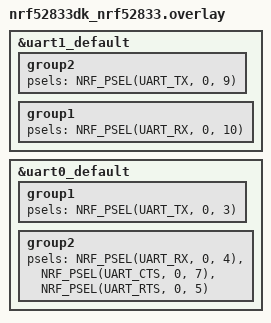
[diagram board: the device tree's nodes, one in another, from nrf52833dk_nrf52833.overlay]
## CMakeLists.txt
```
#*H***********************************************************************
# FILENAME :        CMakeLists.txt
#
# DESCRIPTION :
# CMakeLists file for Zephyr Project.
#
# LICENSE AND COPYRIGHT:
# SPDX-FileCopyrightText: (c) 2023 Siemens AG
# SPDX-License-Identifier: BSD-3-Clause
# 
# NOTES :
# This application is part of the OpenSwarm Project.
#
# AUTHOR :
# Fabian Graf - fabian.graf@siemens.com
#
# CHANGES :
# VERSION DATE    WHO     DETAIL
# 0       26Sep23 FG      Initial Commit
#
#H***********************************************************************/

cmake_minimum_required(VERSION 3.20.0)
find_package(Zephyr REQUIRED HINTS $ENV{ZEPHYR_BASE})

project(aiot_memfault)

target_sources(app PRIVATE src/main.c)

target_sources(app PRIVATE src/ntw.c)
target_sources(app PRIVATE src/ntw.h)
target_sources(app PRIVATE src/periodictimer.c)
target_sources(app PRIVATE src/periodictimer.h)
target_sources(app PRIVATE src/board.c)
target_sources(app PRIVATE src/board.h)

zephyr_include_directories(config)

file(GLOB CLIB 
    "${CMAKE_CURRENT_LIST_DIR}/src/sm_clib-REL-1.0.2.9/sm_clib/*.c"
    "${CMAKE_CURRENT_LIST_DIR}/src/sm_clib-REL-1.0.2.9/sm_clib/*.h"
    "${CMAKE_CURRENT_LIST_DIR}/src/sm_clib-REL-1.0.2.9/sm_clib/ports/aiot_zephyr/*.c"
    "${CMAKE_CURRENT_LIST_DIR}/src/sm_clib-REL-1.0.2.9/sm_clib/ports/aiot_zephyr/*.h")

target_sources(app PRIVATE ${CLIB})
```

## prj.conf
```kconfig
#*H***********************************************************************
# FILENAME :        prj.conf
#
# DESCRIPTION :
# Project Configuration of the Zephyr Project.
#
# LICENSE AND COPYRIGHT:
# SPDX-FileCopyrightText: (c) 2023 Siemens AG
# SPDX-License-Identifier: BSD-3-Clause
# 
# NOTES :
# This application is part of the OpenSwarm Project.
#
# AUTHOR :
# Fabian Graf - fabian.graf@siemens.com
#
# CHANGES :
# VERSION DATE    WHO     DETAIL
# 0       26Sep23 FG      Initial Commit
#
#H***********************************************************************/

# To avoid getting stuck in Bootloader
CONFIG_BOOTLOADER_MCUBOOT=n
CONFIG_SERIAL=y
CONFIG_UART_INTERRUPT_DRIVEN=y

# hwinfo is used to get a unique device id from the chip id
CONFIG_HWINFO=y

# Enable Memfault
CONFIG_MEMFAULT=y
# Below config is set by default in Memfault SDK 0.30.5+
CONFIG_MEMFAULT_NRF_CONNECT_SDK=y

# Use internal flash to store the coredump if desired
CONFIG_MEMFAULT_NCS_INTERNAL_FLASH_BACKED_COREDUMP=y
CONFIG_PM_PARTITION_SIZE_MEMFAULT_STORAGE=0x20000

# Deactivate NCS Metrics to keep payload size small
CONFIG_MEMFAULT_METRICS_DEFAULT_SET_ENABLE=n
CONFIG_MEMFAULT_NCS_STACK_METRICS=n

# set a dummy project key; this setting is required by the nrf-connect
# integration, but it is unused in a non-HTTP application
CONFIG_MEMFAULT_NCS_PROJECT_KEY="***********************"

# Disable root cert storage in our application by setting it to the non-existent
# modem
CONFIG_MEMFAULT_ROOT_CERT_STORAGE_CUSTOM=y

# Set device information fields
CONFIG_MEMFAULT_NCS_DEVICE_ID_RUNTIME=y
CONFIG_MEMFAULT_NCS_HW_VERSION="a"
CONFIG_MEMFAULT_NCS_FW_TYPE="aiot"
CONFIG_MEMFAULT_NCS_FW_VERSION_STATIC=y
CONFIG_MEMFAULT_NCS_FW_VERSION="0.0.1"
```

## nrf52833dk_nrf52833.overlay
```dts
//*H***********************************************************************
// FILENAME :        nrf52833dk_nrf52833.overlay
//
// DESCRIPTION :
// Devicetree Overlay File for the AIOT Board.
//
// LICENSE AND COPYRIGHT:
// SPDX-FileCopyrightText: (c) 2023 Siemens AG
// SPDX-License-Identifier: BSD-3-Clause
// 
// NOTES :
// This application is part of the OpenSwarm Project.
//
// AUTHOR :
// Fabian Graf - fabian.graf@siemens.com
//
// CHANGES :
// VERSION DATE    WHO     DETAIL
// 0       26Sep23 FG      Initial Commit
//
//H***********************************************************************/

// To get started, press Ctrl+Space to bring up the completion menu and view the available nodes.

// You can also use the buttons in the sidebar to perform actions on nodes.
// Actions currently available include:

// * Enabling / disabling the node
// * Adding the bus to a bus
// * Removing the node
// * Connecting ADC channels

// For more help, browse the DeviceTree documentation at https://docs.zephyrproject.org/latest/guides/dts/index.html
// You can also visit the nRF DeviceTree extension documentation at https://nrfconnect.github.io/vscode-nrf-connect/devicetree/nrfdevicetree.html


&uart1_default {
    group2 {
        psels = <NRF_PSEL(UART_TX, 0, 9)>;
    };

    group1 {
        psels = <NRF_PSEL(UART_RX, 0, 10)>;
    };
};

&uart0_default {
    group1 {
        psels = <NRF_PSEL(UART_TX, 0, 3)>;
    };

    group2 {
        psels = <NRF_PSEL(UART_RX, 0, 4)>, <NRF_PSEL(UART_CTS, 0, 7)>, <NRF_PSEL(UART_RTS, 0, 5)>;
    };
};
```

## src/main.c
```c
/*H***********************************************************************
* FILENAME :        main.c
*
* DESCRIPTION :
* A Zephyr application using SmartMesh IP for networking and
* Memfault for monitoring.
*
* LICENSE AND COPYRIGHT:
* SPDX-FileCopyrightText: (c) 2023 Siemens AG
* SPDX-License-Identifier: BSD-3-Clause
* 
* Parts are copied from:
* - aiot_play_fw - INRIA - https://github.com/aiotsystems/aiot_play_fw.git 
* - Memfault Packetizer - Memfault Inc. - 
*   https://docs.memfault.com/docs/mcu/data-from-firmware-to-the-cloud/
*
* NOTES :
* This application is part of the OpenSwarm Project.
*
* AUTHOR :
* Fabian Graf - fabian.graf@siemens.com
*
* CHANGES :
* VERSION DATE    WHO     DETAIL
* 0       26Sep23 FG      Initial Commit
*
*H***********************************************************************/

#include <string.h>
#include <stdbool.h>
#include <stdint.h>
#include <zephyr/kernel.h>
#include <nrf52833.h>
#include "ntw.h"
#include "board.h"
#include "periodictimer.h"
#include <drivers/hwinfo.h>
#include <memfault_ncs.h>
#include <memfault/metrics/metrics.h>
#include <memfault/components.h>
#include "memfault/core/data_packetizer.h"

//=========================== defines =========================================

#define DATA_PERIOD_S 1

//=========================== typedef =========================================

//=========================== variables =======================================

typedef struct {
    uint8_t        txCounter;
} app_vars_t;

app_vars_t app_vars;

typedef struct {
    uint32_t       numReceive;
    uint32_t       numTransmit;
    uint32_t       numTransmit_success;
    uint32_t       numTransmit_fail;
} app_dbg_t;

app_dbg_t app_dbg;

//=========================== prototypes ======================================

void _periodtimer_cb(void);
void _ntw_receive_cb(uint8_t* buf, uint8_t bufLen);
static void set_device_id(void);
static void memfault_init(void);
bool send_memfault_data_multi_part(void);

//=========================== main ============================================

int main(void) {

	  set_device_id();
  	memfault_init();
    
    // initialize variables
    memset(&app_vars,0x00,sizeof(app_vars));
    memset(&app_dbg, 0x00,sizeof(app_dbg));

    // bsp
    board_init();
    
    // ntw
    ntw_init(_ntw_receive_cb);

    // initialize the periodic timer
    periodictimer_init(
        DATA_PERIOD_S,       // period_s
        _periodtimer_cb      // periodtimer_cb
    );

    // main loop
    while(1) {
        // wait for event
        board_sleep();
    }
}

//=========================== private =========================================

void _periodtimer_cb(void) {
    bool success = 0;

    // increment
    app_vars.txCounter++;

	  // Memfault dummy value
	  memfault_metrics_heartbeat_set_unsigned(MEMFAULT_METRICS_KEY(testMetric), app_vars.txCounter);
	  
    // Export
    success = send_memfault_data_multi_part();

    // debug
    app_dbg.numTransmit++;
    if (success==true) {
        app_dbg.numTransmit_success++;
    } else {
        app_dbg.numTransmit_fail++;
    }
}

void _ntw_receive_cb(uint8_t* buf, uint8_t bufLen) {
    
    // debug
    app_dbg.numReceive++;
}

static void set_device_id(void) {
  uint8_t dev_id[16];
  char dev_id_str[33];
  char *dev_str = "UNKNOWN";

  (void)memset(dev_id, 0x0, sizeof(dev_id));

  /* Obtain the device id */
  size_t length = hwinfo_get_device_id(dev_id, sizeof(dev_id));

  /* If this fails for some reason, use a fixed ID instead */
  if (length <= 0) {
    dev_str = CONFIG_SOC_SERIES "-test";
    length = strlen(dev_str);
  } else {
    /* Render the obtained serial number in hexadecimal representation */
    for (size_t i = 0; i < length; i++) {
      //sprintf(&dev_id_str[i * 2], "%02x", dev_id[i]);
    }
    dev_str = dev_id_str;
  }

  printk("Device ID: %s\n", dev_str);

  memfault_ncs_device_id_set(dev_str, length * 2);
}


static void memfault_init(void) {
  static uint8_t s_event_storage[1024];
  const sMemfaultEventStorageImpl *evt_storage =
    memfault_events_storage_boot(s_event_storage, sizeof(s_event_storage));

  // configure trace events to store into the buffer
  memfault_trace_event_boot(evt_storage);

  // record the current reboot reason
  memfault_reboot_tracking_collect_reset_info(evt_storage);

  // configure the metrics component to store into the buffer
  sMemfaultMetricBootInfo boot_info = {
    .unexpected_reboot_count = memfault_reboot_tracking_get_crash_count(),
  };
  memfault_metrics_boot(evt_storage, &boot_info);
}


bool send_memfault_data_multi_part(void) {
  const sPacketizerConfig cfg = {
    // Enable multi packet chunking. This means a chunk may span multiple calls to
    // memfault_packetizer_get_next().
    .enable_multi_packet_chunk = true,
  };

  sPacketizerMetadata metadata;
  bool data_available = memfault_packetizer_begin(&cfg, &metadata);
  if (!data_available) {
    // there are no more chunks to send
    MEMFAULT_LOG_INFO("All data has been sent!");
    return false;
  }

  // Note: metadata.single_chunk_message_length contains the entire length of the chunk
  //
  // This is the "Content-Length" for the HTTP POST request to the Memfault "chunks" endpoint
  //
  // When using HTTP directly on your device, this is where you would start the http request and
  // build the headers

  while (1) {
    uint8_t buffer[80];
    size_t read_size = sizeof(buffer);

    // We pass in the buffer to fill and the size of the buffer.
    // On return, read_size will be populated with how much data was actually written
    eMemfaultPacketizerStatus packetizer_status = memfault_packetizer_get_next(buffer, &read_size);
    if (packetizer_status == kMemfaultPacketizerStatus_NoMoreData) {
      // We know data is available from the memfault_packetizer_begin() call above
      // so _NoMoreData is an unexpected result
      MEMFAULT_LOG_ERROR("Unexpected packetizer status: %d", (int)packetizer_status);
      break;
    }

    // this is the call to a system specific function for sending data over the transport
    ntw_transmit(buffer, read_size);

    if (packetizer_status == kMemfaultPacketizerStatus_EndOfChunk) {
      // we have reached the end of the chunk
      break;
    }
  }

  return true;
}
```

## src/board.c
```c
/*H***********************************************************************
* FILENAME :        board.c
*
* DESCRIPTION :
* Board Configuration file for the AIOT
*
* LICENSE AND COPYRIGHT:
* SPDX-FileCopyrightText: (c) 2022 INRIA
* SPDX-License-Identifier: BSD-3-Clause
*
* This file is copied from:
* - aiot_play_fw - INRIA - https://github.com/aiotsystems/aiot_play_fw.git 
* 
* NOTES :
* This application is part of the OpenSwarm Project.
*
* AUTHOR :
* Thomas Watteyne - thomas.watteyne@inria.fr
*
* CHANGES :
* VERSION DATE    WHO     DETAIL
* 0       27Oct22 TW      Initial Commit
*
*H***********************************************************************/

#include "board.h"

//=========================== variables =======================================

//=========================== prototypes ======================================

//=========================== public ==========================================

void board_init(void) {
    
    // start 32kHz XTAL
    NRF_CLOCK->LFCLKSRC                = 0x00000001; // 1==XTAL
    NRF_CLOCK->EVENTS_LFCLKSTARTED     = 0;
    NRF_CLOCK->TASKS_LFCLKSTART        = 0x00000001;
    while (NRF_CLOCK->EVENTS_LFCLKSTARTED == 0);
    
    // start HFCLK
    NRF_CLOCK->EVENTS_HFCLKSTARTED     = 0;
    NRF_CLOCK->TASKS_HFCLKSTART        = 0x00000001;
    while (NRF_CLOCK->EVENTS_HFCLKSTARTED == 0);
}

void board_sleep(void) {
    // wait for event
    __SEV(); // set event
    __WFE(); // wait for event
    __WFE(); // wait for event
}

//=========================== private =========================================

//=========================== interrupt handlers ==============================
```

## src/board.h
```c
/*H***********************************************************************
* FILENAME :        board.h
*
* DESCRIPTION :
* Board Configuration file for the AIOT
*
* LICENSE AND COPYRIGHT:
* SPDX-FileCopyrightText: (c) 2022 INRIA
* SPDX-License-Identifier: BSD-3-Clause
*
* This file is copied from:
* - aiot_play_fw - INRIA - https://github.com/aiotsystems/aiot_play_fw.git 
* 
* NOTES :
* This application is part of the OpenSwarm Project.
*
* AUTHOR :
* Thomas Watteyne - thomas.watteyne@inria.fr
*
* CHANGES :
* VERSION DATE    WHO     DETAIL
* 0       27Oct22 TW      Initial Commit
*
*H***********************************************************************/

#ifndef __BOARD_H
#define __BOARD_H

#include <nrf52833.h>

//=========================== define ==========================================

//=========================== typedef =========================================

//=========================== variables =======================================

//=========================== prototypes ======================================

void board_init(void);
void board_sleep(void);

#endif
```

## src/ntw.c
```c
/*H***********************************************************************
* FILENAME :        ntw.c
*
* DESCRIPTION :
* Networking Interface of the AIOT Board
*
* LICENSE AND COPYRIGHT:
* SPDX-FileCopyrightText: (c) 2023 Siemens AG and INRIA
* SPDX-License-Identifier: BSD-3-Clause
* 
* Parts are copied from:
* - aiot_play_fw - INRIA - https://github.com/aiotsystems/aiot_play_fw.git 
*
* NOTES :
* This application is part of the OpenSwarm Project.
*
* AUTHOR :
* Fabian Graf - fabian.graf@siemens.com
*
* CHANGES :
* VERSION DATE    WHO     DETAIL
* 0       26Sep23 FG      Initial Commit
*
*H***********************************************************************/

#include <zephyr/kernel.h>
#include <stdint.h>
#include <nrf52833.h>
#include "sm_clib-REL-1.0.2.9/sm_clib/dn_ipmt.h"
#include "ntw.h"

//=========================== defines =========================================

// mote state
#define MOTE_STATE_IDLE           0x01
#define MOTE_STATE_SEARCHING      0x02
#define MOTE_STATE_NEGOCIATING    0x03
#define MOTE_STATE_CONNECTED      0x04
#define MOTE_STATE_OPERATIONAL    0x05

// service types
#define SERVICE_TYPE_BW           0x00

// timings
#define SERIAL_RESPONSE_TIMEOUT   16384          // 16384@32kHz = 500ms
#define CMD_PERIOD                32768          // 32768@32kHz = 1s

// api
#define SRC_PORT                  0xf0b8
#define DST_PORT                  0xf0b8

//=========================== typedefs ========================================

typedef void (*fsm_timer_callback)(void);
typedef void (*fsm_reply_callback)(void);

//=========================== variables =======================================

typedef struct {
    // interface
    ntw_receive_cbt     ntw_receive_cb;
    // ipmt
    bool                isOper;                            // true iff is operational
    uint8_t             socketId;                          // ID of the mote's UDP socket
    uint8_t             replyBuf[MAX_FRAME_LENGTH];        // holds notifications from ipmt
    uint8_t             notifBuf[MAX_FRAME_LENGTH];        // notifications buffer internal to ipmt
    // fsm
    fsm_timer_callback  fsmCb;
    // reply
    fsm_reply_callback  replyCb;
} ntw_vars_t;

ntw_vars_t ntw_vars;

typedef struct {
    uint32_t            num_calls_api_getMoteStatus;
    uint32_t            num_calls_api_getMoteStatus_reply;
    uint32_t            num_calls_api_openSocket;
    uint32_t            num_calls_api_openSocket_reply;
    uint32_t            num_calls_api_bindSocket;
    uint32_t            num_calls_api_bindSocket_reply;
    uint32_t            num_calls_api_join;
    uint32_t            num_calls_api_join_reply;
    uint32_t            num_calls_api_sendTo;
    uint32_t            num_calls_api_sendTo_reply;
    uint32_t            num_notif_EVENTS;
    uint32_t            num_notif_RECEIVE;
    uint32_t            num_ISR_RTC1_IRQHandler;
    uint32_t            num_ISR_RTC1_IRQHandler_COMPARE0;
} ntw_dbg_t;

ntw_dbg_t ntw_dbg;
struct k_timer my_timer;

//=========================== prototypes ======================================

// fsm
void     fsm_scheduleEvent(uint16_t delay, fsm_timer_callback cb);
void     fsm_cancelEvent(void);
void     fsm_setCallback(fsm_reply_callback cb);
// ipmt
void     dn_ipmt_notif_cb(uint8_t cmdId, uint8_t subCmdId);
void     dn_ipmt_reply_cb(uint8_t cmdId);
// api
void     api_response_timeout(void);
void     api_getMoteStatus(void);
void     api_getMoteStatus_reply(void);
void     api_openSocket(void);
void     api_openSocket_reply(void);
void     api_bindSocket(void);
void     api_bindSocket_reply(void);
void     api_join(void);
void     api_join_reply(void);
bool     api_sendTo(uint8_t* buf, uint8_t bufLen);
void     api_sendTo_reply(void);
// bsp
void     lfxtal_start(void);
void     hfclock_start(void);
// irq
void     RTC1_IRQHandler(void);

//=========================== public ==========================================

void ntw_init(ntw_receive_cbt ntw_receive_cb) {

    // reset variables
    memset(&ntw_vars,0x00,sizeof(ntw_vars_t));
    ntw_vars.socketId = 22; // default value
    memset(&ntw_dbg, 0x00,sizeof(ntw_dbg_t));

    // store params
    ntw_vars.ntw_receive_cb = ntw_receive_cb;

    // initialize the ipmt module
    dn_ipmt_init(
        dn_ipmt_notif_cb,                // notifCb
        ntw_vars.notifBuf,               // notifBuf
        sizeof(ntw_vars.notifBuf),       // notifBufLen
        dn_ipmt_reply_cb                 // replyCb
    );

    // initialize timer
    k_timer_init(&my_timer, RTC1_IRQHandler, NULL);

    // schedule the first event
    fsm_scheduleEvent(CMD_PERIOD, &api_getMoteStatus);
}

bool ntw_transmit(uint8_t* buf, uint8_t bufLen) {
    return api_sendTo(buf, bufLen);
}

//=========================== private =========================================

//=== fsm

void fsm_scheduleEvent(uint16_t delay, fsm_timer_callback cb) {
   
    // remember what function to call
    ntw_vars.fsmCb                     = cb;
    k_timer_start(&my_timer, K_MSEC(125), K_MSEC(125));
    
}

void fsm_cancelEvent(void) {
   k_timer_stop(&my_timer);
   
   // clear function to call
   ntw_vars.fsmCb                      = NULL;
}

void fsm_setCallback(fsm_reply_callback cb) {
   ntw_vars.replyCb                    = cb;
}

//=== ipmt

void dn_ipmt_notif_cb(uint8_t cmdId, uint8_t subCmdId) {
    dn_ipmt_events_nt*   dn_ipmt_events_notif;
    dn_ipmt_receive_nt*  dn_ipmt_receive_notif;

    switch (cmdId) {
      case CMDID_EVENTS:
   
          // debug
          ntw_dbg.num_notif_EVENTS++;

          // parse
          dn_ipmt_events_notif = (dn_ipmt_events_nt*)ntw_vars.notifBuf;

          // handle
          switch (dn_ipmt_events_notif->state) {
              case MOTE_STATE_IDLE:
                  ntw_vars.isOper = false;
                  fsm_scheduleEvent(CMD_PERIOD,api_getMoteStatus);
                  break;
              case MOTE_STATE_OPERATIONAL:
                  ntw_vars.isOper = true;
                  break;
              default:
                  // nothing to do
                  break;
          }
          break;
      case CMDID_RECEIVE:
          
          // debug
          ntw_dbg.num_notif_RECEIVE++;

          // parse
          dn_ipmt_receive_notif = (dn_ipmt_receive_nt*)ntw_vars.notifBuf;

          // notify app
          ntw_vars.ntw_receive_cb(
              dn_ipmt_receive_notif->payload,
              dn_ipmt_receive_notif->payloadLen
          );

      default:
         // nothing to do
         break;
    }
}

void dn_ipmt_reply_cb(uint8_t cmdId) {
   ntw_vars.replyCb();
}

//=== api

void api_response_timeout(void) {
   
   // issue cancel command
   dn_ipmt_cancelTx();
   
   // schedule first event
   fsm_scheduleEvent(CMD_PERIOD, &api_getMoteStatus);
}

// getMoteStatus

void api_getMoteStatus(void) {
   
   // debug
   ntw_dbg.num_calls_api_getMoteStatus++;

   // arm callback
   fsm_setCallback(api_getMoteStatus_reply);
   
   // issue function
   dn_ipmt_getParameter_moteStatus(
      (dn_ipmt_getParameter_moteStatus_rpt*)(ntw_vars.replyBuf)
   );

   // schedule timeout event
   fsm_scheduleEvent(SERIAL_RESPONSE_TIMEOUT, api_response_timeout);
}

void api_getMoteStatus_reply(void) {
   dn_ipmt_getParameter_moteStatus_rpt* reply;
   
   // debug
   ntw_dbg.num_calls_api_getMoteStatus_reply++;

   // cancel timeout
   fsm_cancelEvent();
   
   // parse reply
   reply = (dn_ipmt_getParameter_moteStatus_rpt*)ntw_vars.replyBuf;
   
   // choose next step
   switch (reply->state) {
      case MOTE_STATE_IDLE:
         ntw_vars.isOper = false;
         fsm_scheduleEvent(CMD_PERIOD, &api_openSocket);
         break;
      case MOTE_STATE_OPERATIONAL:
         ntw_vars.isOper = true;
         break;
      default:
         ntw_vars.isOper = false;
         fsm_scheduleEvent(CMD_PERIOD, api_getMoteStatus);
         break;
   }
}

// openSocket

void api_openSocket(void) {
  
   // debug
   ntw_dbg.num_calls_api_openSocket++;

   // arm callback
   fsm_setCallback(api_openSocket_reply);
   
   // issue function
   dn_ipmt_openSocket(
      0,                                              // protocol
      (dn_ipmt_openSocket_rpt*)(ntw_vars.replyBuf)    // reply
   );
   
   // schedule timeout event
   fsm_scheduleEvent(SERIAL_RESPONSE_TIMEOUT, api_response_timeout);
}

void api_openSocket_reply(void) {
   dn_ipmt_openSocket_rpt* reply;
   
   // debug
   ntw_dbg.num_calls_api_openSocket_reply++;

   // cancel timeout
   fsm_cancelEvent();
   
   // parse reply
   reply = (dn_ipmt_openSocket_rpt*)ntw_vars.replyBuf;
   
   // store the socketID
   ntw_vars.socketId = reply->socketId;
   
   // choose next step
   fsm_scheduleEvent(CMD_PERIOD, api_bindSocket);
}

// bindSocket

void api_bindSocket(void) {
   
   // debug
   ntw_dbg.num_calls_api_bindSocket++;

   // arm callback
   fsm_setCallback(api_bindSocket_reply);
   
   // issue function
   dn_ipmt_bindSocket(
      ntw_vars.socketId,                              // socketId
      SRC_PORT,                                       // port
      (dn_ipmt_bindSocket_rpt*)(ntw_vars.replyBuf)    // reply
   );

   // schedule timeout event
   fsm_scheduleEvent(SERIAL_RESPONSE_TIMEOUT, api_response_timeout);
}

void api_bindSocket_reply(void) {
   
   // debug
   ntw_dbg.num_calls_api_bindSocket_reply++;

   // cancel timeout
   fsm_cancelEvent();
   
   // choose next step
   fsm_scheduleEvent(CMD_PERIOD, api_join);
}

// join

void api_join(void) {
   
   // debug
   ntw_dbg.num_calls_api_join++;

   // arm callback
   fsm_setCallback(api_join_reply);
   
   // issue function
   dn_ipmt_join(
      (dn_ipmt_join_rpt*)(ntw_vars.replyBuf)     // reply
   );

   // schedule timeout event
   fsm_scheduleEvent(SERIAL_RESPONSE_TIMEOUT, api_response_timeout);
}

void api_join_reply(void) {

   // debug
   ntw_dbg.num_calls_api_join_reply++;

   // cancel timeout
   fsm_cancelEvent();
   
   // choose next step
   // no next step at this point. FSM will advance when we received a "joined"
   // notification
}

// sendTo

bool api_sendTo(uint8_t* buf, uint8_t bufLen) {
   bool     returnVal;
   uint8_t  dest_addr[16];
   dn_err_t dn_err;
   
   if (ntw_vars.isOper==true) {
      // mote is operational

      // debug
      ntw_dbg.num_calls_api_sendTo++;

      // arm callback
      fsm_setCallback(api_sendTo_reply);

      // populate address
      memcpy(dest_addr,ipv6Addr_manager,16);

      // issue function
      dn_err = dn_ipmt_sendTo(
        ntw_vars.socketId,                                   // socketId
        dest_addr,                                           // destIP
        DST_PORT,                                            // destPort
        SERVICE_TYPE_BW,                                     // serviceType
        0,                                                   // priority
        0xffff,                                              // packetId
        buf,                                                 // payload
        bufLen,                                              // payloadLen
        (dn_ipmt_sendTo_rpt*)(ntw_vars.replyBuf)             // reply
      );

      // prepare returnVal
      if (dn_err==DN_ERR_NONE) {
          returnVal = true;
      } else {
          returnVal = false;
      }

      // schedule timeout event
      fsm_scheduleEvent(SERIAL_RESPONSE_TIMEOUT, api_response_timeout);
   } else {
      // mote is NOT operational

      // cannot proceed
      returnVal = false;
   }

   return returnVal;
}

void api_sendTo_reply(void) {
   
   // debug
   ntw_dbg.num_calls_api_sendTo_reply++;

   // cancel timeout
   fsm_cancelEvent();
}

//=========================== interrupt handlers ==============================

void RTC1_IRQHandler(void) {

    // debug
    ntw_dbg.num_ISR_RTC1_IRQHandler++;
    ntw_vars.fsmCb();
}
```

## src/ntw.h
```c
/*H***********************************************************************
* FILENAME :        ntw.c
*
* DESCRIPTION :
* Networking Interface of the AIOT Board
*
* LICENSE AND COPYRIGHT:
* SPDX-FileCopyrightText: (c) 2023 Siemens AG and INRIA
* SPDX-License-Identifier: BSD-3-Clause
* 
* Parts are copied from:
* - aiot_play_fw - INRIA - https://github.com/aiotsystems/aiot_play_fw.git 
*
* NOTES :
* This application is part of the OpenSwarm Project.
*
* AUTHOR :
* Fabian Graf - fabian.graf@siemens.com
*
* CHANGES :
* VERSION DATE    WHO     DETAIL
* 0       26Sep23 FG      Initial Commit
*
*H***********************************************************************/

#ifndef __NTW_H
#define __NTW_H

#include <stdbool.h>
#include <stdint.h>

//=========================== define ==========================================

//=========================== typedef =========================================

typedef void (*ntw_receive_cbt)(uint8_t* buf, uint8_t bufLen);

//=========================== variables =======================================

//=========================== prototypes ======================================

void ntw_init(ntw_receive_cbt ntw_receive_cb);
bool ntw_transmit(uint8_t* buf, uint8_t bufLen);

#endif
```

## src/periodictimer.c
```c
/*H***********************************************************************
* FILENAME :        periodictimer.c
*
* DESCRIPTION :
* Periodic Timer in Zephyr for an AIOT sample application
*
* LICENSE AND COPYRIGHT:
* SPDX-FileCopyrightText: (c) 2023 Siemens AG and INRIA
* SPDX-License-Identifier: BSD-3-Clause
* 
* Parts are copied from:
* - aiot_play_fw - INRIA - https://github.com/aiotsystems/aiot_play_fw.git 
*
* NOTES :
* This application is part of the OpenSwarm Project.
*
* AUTHOR :
* Fabian Graf - fabian.graf@siemens.com
*
* CHANGES :
* VERSION DATE    WHO     DETAIL
* 0       26Sep23 FG      Initial Commit
*
*H***********************************************************************/

#include <string.h>
#include <nrf52833.h>
#include <zephyr/kernel.h>
#include "periodictimer.h"

//=========================== define ==========================================

//=========================== variables =======================================

typedef struct {
    uint16_t        period_s;
    periodtimer_cbt periodtimer_cb;
    uint16_t        countdown_s;
} periodictimer_vars_t;

periodictimer_vars_t periodictimer_vars;

typedef struct {
    uint32_t        num_ISR_RTC0_IRQHandler;
    uint32_t        num_ISR_RTC0_IRQHandler_COMPARE0;
} periodictimer_dbg_t;

periodictimer_dbg_t periodictimer_dbg;
struct k_timer periodic_zephyr_timer;

//=========================== prototypes ======================================

void RTC0_IRQHandler(void);

//=========================== public ==========================================

void periodictimer_init(uint16_t period_s, periodtimer_cbt periodtimer_cb) {

    // reset variables
    memset(&periodictimer_vars,0x00,sizeof(periodictimer_vars_t));
    // store params
    periodictimer_vars.period_s        = period_s;
    periodictimer_vars.periodtimer_cb  = periodtimer_cb;
    // initialize timer
    k_timer_init(&periodic_zephyr_timer, RTC0_IRQHandler, NULL);
    periodictimer_vars.countdown_s     = periodictimer_vars.period_s;
    k_timer_start(&periodic_zephyr_timer, K_MSEC(period_s*1000), K_MSEC(period_s*1000));
}

//=========================== private =========================================

//=========================== interrupt handlers ==============================

void RTC0_IRQHandler(void) {
   // debug
   periodictimer_dbg.num_ISR_RTC0_IRQHandler++;
   periodictimer_vars.countdown_s--;
   periodictimer_vars.countdown_s = periodictimer_vars.period_s;
   periodictimer_vars.periodtimer_cb();
}
```

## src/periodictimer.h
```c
/*H***********************************************************************
* FILENAME :        periodictimer.h
*
* DESCRIPTION :
* Periodic Timer in Zephyr for an AIOT sample application
*
* LICENSE AND COPYRIGHT:
* SPDX-FileCopyrightText: (c) 2023 Siemens AG and INRIA
* SPDX-License-Identifier: BSD-3-Clause
* 
* Parts are copied from:
* - aiot_play_fw - INRIA - https://github.com/aiotsystems/aiot_play_fw.git 
*
* NOTES :
* This application is part of the OpenSwarm Project.
*
* AUTHOR :
* Fabian Graf - fabian.graf@siemens.com
*
* CHANGES :
* VERSION DATE    WHO     DETAIL
* 0       26Sep23 FG      Initial Commit
*
*H***********************************************************************/

#ifndef __PERIODICTIMER_H
#define __PERIODICTIMER_H

#include "nrf52833.h"

//=========================== define ==========================================

//=========================== typedef =========================================

typedef void (*periodtimer_cbt)(void);

//=========================== variables =======================================

//=========================== prototypes ======================================

void periodictimer_init(uint16_t period_s, periodtimer_cbt periodtimer_cb);

#endif
```
